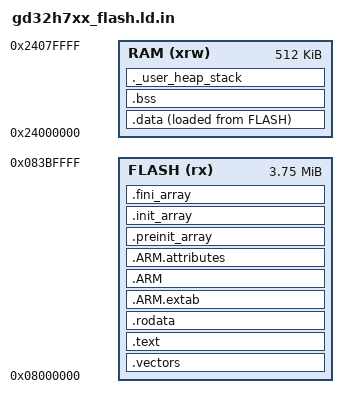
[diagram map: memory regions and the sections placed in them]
_estack = ORIGIN(RAM) + LENGTH(RAM);    /* end of RAM */
_Min_Heap_Size = @MIN_HEAP_SIZE@;
_Min_Stack_Size = @MIN_STACK_SIZE@;

/* memory map */
MEMORY
{
  FLASH (rx)      : ORIGIN = 0x08000000, LENGTH = 3840K
  RAM (xrw)       : ORIGIN = 0x24000000, LENGTH = 512K
}

ENTRY(Reset_Handler)

SECTIONS
{
  
/* ISR vectors */
  .vectors :
  {
    . = ALIGN(4);
    KEEP(*(.vectors))
    . = ALIGN(4);
    __Vectors_End = .;
    __Vectors_Size = __Vectors_End - __gVectors;
  } >FLASH

  .text :
  {
    . = ALIGN(4);
    *(.text)
    *(.text*)
    *(.glue_7) 
    *(.glue_7t)
    *(.eh_frame)

    KEEP (*(.init))
    KEEP (*(.fini))

    . = ALIGN(4);
    /* the symbol ‘_etext’ will be defined at the end of code section */
    _etext = .;
  } >FLASH

  .rodata :
  {
    . = ALIGN(4);
    *(.rodata)
    *(.rodata*)
    . = ALIGN(4);
  } >FLASH

   .ARM.extab :
  { 
     *(.ARM.extab* .gnu.linkonce.armextab.*) 
  } >FLASH
  
    .ARM : {
    __exidx_start = .;
    *(.ARM.exidx*)
    __exidx_end = .;
    } >FLASH

  .ARM.attributes : { *(.ARM.attributes) } > FLASH

  .preinit_array :
  {
    PROVIDE_HIDDEN (__preinit_array_start = .);
    KEEP (*(.preinit_array*))
    PROVIDE_HIDDEN (__preinit_array_end = .);
  } >FLASH
  
  .init_array :
  {
    PROVIDE_HIDDEN (__init_array_start = .);
    KEEP (*(SORT(.init_array.*)))
    KEEP (*(.init_array*))
    PROVIDE_HIDDEN (__init_array_end = .);
  } >FLASH
  
  .fini_array :
  {
    PROVIDE_HIDDEN (__fini_array_start = .);
    KEEP (*(.fini_array*))
    KEEP (*(SORT(.fini_array.*)))
    PROVIDE_HIDDEN (__fini_array_end = .);
  } >FLASH

  /* provide some necessary symbols for startup file to initialize data */
  _sidata = LOADADDR(.data);
  .data :
  {
    . = ALIGN(4);
    /* the symbol ‘_sdata’ will be defined at the data section end start */
    _sdata = .;
    *(.data)
    *(.data*)
    . = ALIGN(4);
    /* the symbol ‘_edata’ will be defined at the data section end */
    _edata = .;
  } >RAM AT> FLASH

  . = ALIGN(4);
  .bss :
  {
    /* the symbol ‘_sbss’ will be defined at the bss section start */
    _sbss = .;
    __bss_start__ = _sbss;
    *(.bss)
    *(.bss*)
    *(COMMON)
    . = ALIGN(4);
    /* the symbol ‘_ebss’ will be defined at the bss section end */
    _ebss = .;
    __bss_end__ = _ebss;
  } >RAM

 . = ALIGN(8);
  PROVIDE ( end = _ebss );
  PROVIDE ( _end = _ebss );

  /* User_heap_stack section, used to check that there is enough RAM left */
  ._user_heap_stack :
  {
    . = ALIGN(8);                 /* 对齐到8字节边界 */
    PROVIDE ( end = . );          /* 定义end符号为当前地址 */
    PROVIDE ( _end = . );         /* 定义_end符号为当前地址 */
    . = . + _Min_Heap_Size;       /* 加上堆的大小 */
    . = . + _Min_Stack_Size;      /* 加上栈的大小 */
    PROVIDE ( _sp = . );          /* 定义_sp为当前地址，即栈的起始地址 */
    . = ALIGN(8);                 /* 对齐到8字节边界 */
  } >RAM

  /* Remove information from the standard libraries */
  /DISCARD/ :
  {
    libc.a ( * )
    libm.a ( * )
    libgcc.a ( * )
  }
}
